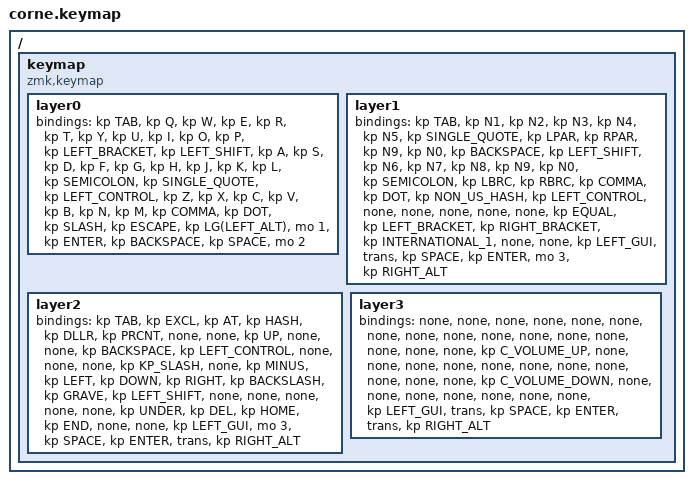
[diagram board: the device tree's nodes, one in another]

  /*
  * Copyright (c) 2020 The ZMK Contributors
  *
  * SPDX-License-Identifier: MIT
  */

  #include <behaviors.dtsi>
  #include <dt-bindings/zmk/keys.h>
  #include <dt-bindings/zmk/bt.h>
  #include <dt-bindings/zmk/ext_power.h>

  / {
    keymap {
      compatible = "zmk,keymap";
  layer0 {
          bindings = <
          &kp TAB &kp Q &kp W &kp E &kp R &kp T &kp Y &kp U &kp I &kp O &kp P &kp LEFT_BRACKET &kp LEFT_SHIFT &kp A &kp S &kp D &kp F &kp G &kp H &kp J &kp K &kp L &kp SEMICOLON &kp SINGLE_QUOTE &kp LEFT_CONTROL &kp Z &kp X &kp C &kp V &kp B &kp N &kp M &kp COMMA &kp DOT &kp SLASH &kp ESCAPE &kp LG(LEFT_ALT) &mo 1 &kp ENTER &kp BACKSPACE &kp SPACE &mo 2
          >;
        };layer1 {
          bindings = <
          &kp TAB &kp N1 &kp N2 &kp N3 &kp N4 &kp N5 &kp SINGLE_QUOTE &kp LPAR &kp RPAR &kp N9 &kp N0 &kp BACKSPACE &kp LEFT_SHIFT &kp N6 &kp N7 &kp N8 &kp N9 &kp N0 &kp SEMICOLON &kp LBRC &kp RBRC &kp COMMA &kp DOT &kp NON_US_HASH &kp LEFT_CONTROL &none &none &none &none &none &kp EQUAL &kp LEFT_BRACKET &kp RIGHT_BRACKET &kp INTERNATIONAL_1 &none &none &kp LEFT_GUI &trans &kp SPACE &kp ENTER &mo 3 &kp RIGHT_ALT
          >;
        };layer2 {
          bindings = <
          &kp TAB &kp EXCL &kp AT &kp HASH &kp DLLR &kp PRCNT &none &none &kp UP &none &none &kp BACKSPACE &kp LEFT_CONTROL &none &none &none &kp KP_SLASH &none &kp MINUS &kp LEFT &kp DOWN &kp RIGHT &kp BACKSLASH &kp GRAVE &kp LEFT_SHIFT &none &none &none &none &none &kp UNDER &kp DEL &kp HOME &kp END &none &none &kp LEFT_GUI &mo 3 &kp SPACE &kp ENTER &trans &kp RIGHT_ALT
          >;
        };layer3 {
          bindings = <
          &none &none &none &none &none &none &none &none &none &none &none &none &none &none &none &none &kp C_VOLUME_UP &none &none &none &none &none &none &none &none &none &none &none &kp C_VOLUME_DOWN &none &none &none &none &none &none &none &kp LEFT_GUI &trans &kp SPACE &kp ENTER &trans &kp RIGHT_ALT
          >;
        };
    };
  };
  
